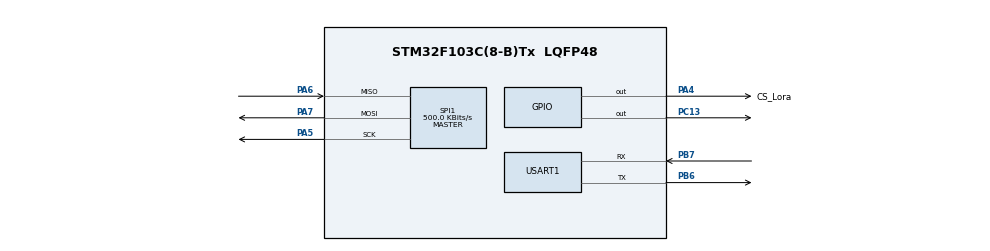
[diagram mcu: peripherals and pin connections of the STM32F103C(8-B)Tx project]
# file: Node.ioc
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Mcu.Family=STM32F1
Mcu.Name=STM32F103C(8-B)Tx
Mcu.Package=LQFP48
NVIC.PriorityGroup=NVIC_PRIORITYGROUP_4
PA13.Mode=Serial_Wire
PA13.Signal=SYS_JTMS-SWDIO
PA14.Mode=Serial_Wire
PA14.Signal=SYS_JTCK-SWCLK
PA4.GPIO_Label=CS_Lora
PA4.GPIO_PuPd=GPIO_PULLUP
PA4.PinState=GPIO_PIN_RESET
PA4.Signal=GPIO_Output
PA5.Mode=Full_Duplex_Master
PA5.Signal=SPI1_SCK
PA6.Mode=Full_Duplex_Master
PA6.Signal=SPI1_MISO
PA7.Mode=Full_Duplex_Master
PA7.Signal=SPI1_MOSI
PB6.Mode=Asynchronous
PB6.Signal=USART1_TX
PB7.Mode=Asynchronous
PB7.Signal=USART1_RX
PC13-TAMPER-RTC.Signal=GPIO_Output
ProjectManager.HeapSize=0x200
ProjectManager.StackSize=0x400
ProjectManager.TargetToolchain=CMake
RCC.APB1Freq_Value=8000000
RCC.APB2Freq_Value=8000000
SPI1.BaudRatePrescaler=SPI_BAUDRATEPRESCALER_16
SPI1.CLKPhase=SPI_PHASE_2EDGE
SPI1.CLKPolarity=SPI_POLARITY_LOW
SPI1.CalculateBaudRate=500.0 KBits/s
SPI1.DataSize=SPI_DATASIZE_8BIT
SPI1.Direction=SPI_DIRECTION_2LINES
SPI1.FirstBit=SPI_FIRSTBIT_MSB
SPI1.Mode=SPI_MODE_MASTER
SPI1.VirtualType=VM_MASTER
USART1.VirtualMode=VM_ASYNC
board=custom

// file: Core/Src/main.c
/* USER CODE BEGIN Header */
/**
 ******************************************************************************
 * @file           : main.c
 * @brief          : Main program body
 ******************************************************************************
 * @attention
 *
 * Copyright (c) 2025 STMicroelectronics.
 * All rights reserved.
 *
 * This software is licensed under terms that can be found in the LICENSE file
 * in the root directory of this software component.
 * If no LICENSE file comes with this software, it is provided AS-IS.
 *
 ******************************************************************************
 */
/* USER CODE END Header */
#include "main.h"

/* USER CODE BEGIN Includes */
#include <stdio.h>
#include "app.h"
#include "stm32f1xx_hal_gpio.h"
/* USER CODE END Includes */

/* USER CODE BEGIN PTD */
UART_HandleTypeDef huart1;
/* USER CODE END PTD */

SPI_HandleTypeDef hspi1;
extern ADC_HandleTypeDef hadc1;
UART_HandleTypeDef huart1;

void SystemClock_Config(void);
static void MX_GPIO_Init(void);
static void MX_USART1_UART_Init(void);
static void MX_SPI1_Init(void);

int main(void)
{

  /* MCU Configuration--------------------------------------------------------*/

  /* Reset of all peripherals, Initializes the Flash interface and the Systick. */
  HAL_Init();

  /* Configure the system clock */
  SystemClock_Config();

  /* Initialize all configured peripherals */
  MX_GPIO_Init();
  MX_USART1_UART_Init();
  MX_SPI1_Init();
  /* USER CODE BEGIN 2 */
  App_Init();
  /* USER CODE END 2 */

  /* Infinite loop */
  while (1) {

    /* USER CODE BEGIN 3 */
    App_Start();

  }
  /* USER CODE END 3 */
}

void SystemClock_Config(void)
{
  RCC_OscInitTypeDef RCC_OscInitStruct = {0};
  RCC_ClkInitTypeDef RCC_ClkInitStruct = {0};

  /** Initializes the RCC Oscillators according to the specified parameters
  * in the RCC_OscInitTypeDef structure.
  */
  RCC_OscInitStruct.OscillatorType = RCC_OSCILLATORTYPE_HSI;
  RCC_OscInitStruct.HSIState = RCC_HSI_ON;
  RCC_OscInitStruct.HSICalibrationValue = RCC_HSICALIBRATION_DEFAULT;
  RCC_OscInitStruct.PLL.PLLState = RCC_PLL_NONE;
  if (HAL_RCC_OscConfig(&RCC_OscInitStruct) != HAL_OK)
  {
    Error_Handler();
  }

  /** Initializes the CPU, AHB and APB buses clocks
  */
  RCC_ClkInitStruct.ClockType = RCC_CLOCKTYPE_HCLK|RCC_CLOCKTYPE_SYSCLK
                              |RCC_CLOCKTYPE_PCLK1|RCC_CLOCKTYPE_PCLK2;
  RCC_ClkInitStruct.SYSCLKSource = RCC_SYSCLKSOURCE_HSI;
  RCC_ClkInitStruct.AHBCLKDivider = RCC_SYSCLK_DIV1;
  RCC_ClkInitStruct.APB1CLKDivider = RCC_HCLK_DIV1;
  RCC_ClkInitStruct.APB2CLKDivider = RCC_HCLK_DIV1;

  if (HAL_RCC_ClockConfig(&RCC_ClkInitStruct, FLASH_LATENCY_0) != HAL_OK)
  {
    Error_Handler();
  }
}

static void MX_SPI1_Init(void)
{

  /* SPI1 parameter configuration*/
  hspi1.Instance = SPI1;
  hspi1.Init.Mode = SPI_MODE_MASTER;
  hspi1.Init.Direction = SPI_DIRECTION_2LINES;
  hspi1.Init.DataSize = SPI_DATASIZE_8BIT;
  hspi1.Init.CLKPolarity = SPI_POLARITY_LOW;
  hspi1.Init.CLKPhase = SPI_PHASE_2EDGE;
  hspi1.Init.NSS = SPI_NSS_SOFT;
  hspi1.Init.BaudRatePrescaler = SPI_BAUDRATEPRESCALER_16;
  hspi1.Init.FirstBit = SPI_FIRSTBIT_MSB;
  hspi1.Init.TIMode = SPI_TIMODE_DISABLE;
  hspi1.Init.CRCCalculation = SPI_CRCCALCULATION_DISABLE;
  hspi1.Init.CRCPolynomial = 10;
  if (HAL_SPI_Init(&hspi1) != HAL_OK)
  {
    Error_Handler();
  }

}

static void MX_USART1_UART_Init(void)
{

  huart1.Instance = USART1;
  huart1.Init.BaudRate = 115200;
  huart1.Init.WordLength = UART_WORDLENGTH_8B;
  huart1.Init.StopBits = UART_STOPBITS_1;
  huart1.Init.Parity = UART_PARITY_NONE;
  huart1.Init.Mode = UART_MODE_TX_RX;
  huart1.Init.HwFlowCtl = UART_HWCONTROL_NONE;
  huart1.Init.OverSampling = UART_OVERSAMPLING_16;
  if (HAL_UART_Init(&huart1) != HAL_OK)
  {
    Error_Handler();
  }

}

static void MX_GPIO_Init(void)
{
  GPIO_InitTypeDef GPIO_InitStruct = {0};

  /* GPIO Ports Clock Enable */
  __HAL_RCC_GPIOC_CLK_ENABLE();
  __HAL_RCC_GPIOA_CLK_ENABLE();
  __HAL_RCC_GPIOB_CLK_ENABLE();

  /*Configure GPIO pin Output Level */
  HAL_GPIO_WritePin(GPIOC, GPIO_PIN_13, GPIO_PIN_RESET);

  /*Configure GPIO pin Output Level */
  HAL_GPIO_WritePin(CS_Lora_GPIO_Port, CS_Lora_Pin, GPIO_PIN_RESET);

  /*Configure GPIO pin : PC13 */
  GPIO_InitStruct.Pin = GPIO_PIN_13;
  GPIO_InitStruct.Mode = GPIO_MODE_OUTPUT_PP;
  GPIO_InitStruct.Pull = GPIO_NOPULL;
  GPIO_InitStruct.Speed = GPIO_SPEED_FREQ_LOW;
  HAL_GPIO_Init(GPIOC, &GPIO_InitStruct);

  /*Configure GPIO pin : CS_Lora_Pin */
  GPIO_InitStruct.Pin = CS_Lora_Pin;
  GPIO_InitStruct.Mode = GPIO_MODE_OUTPUT_PP;
  GPIO_InitStruct.Pull = GPIO_PULLUP;
  GPIO_InitStruct.Speed = GPIO_SPEED_FREQ_LOW;
  HAL_GPIO_Init(CS_Lora_GPIO_Port, &GPIO_InitStruct);

}

void Error_Handler(void)
{
  __disable_irq();
  while (1) {
  }
}
#ifdef USE_FULL_ASSERT
/**
  * @brief  Reports the name of the source file and the source line number
  *         where the assert_param error has occurred.
  * @param  file: pointer to the source file name
  * @param  line: assert_param error line source number
  * @retval None
  */
void assert_failed(uint8_t *file, uint32_t line)
{
  /* USER CODE BEGIN 6 */
  /* User can add his own implementation to report the file name and line
     number, ex: printf("Wrong parameters value: file %s on line %d\r\n", file,
     line) */
  /* USER CODE END 6 */
}
#endif /* USE_FULL_ASSERT */
